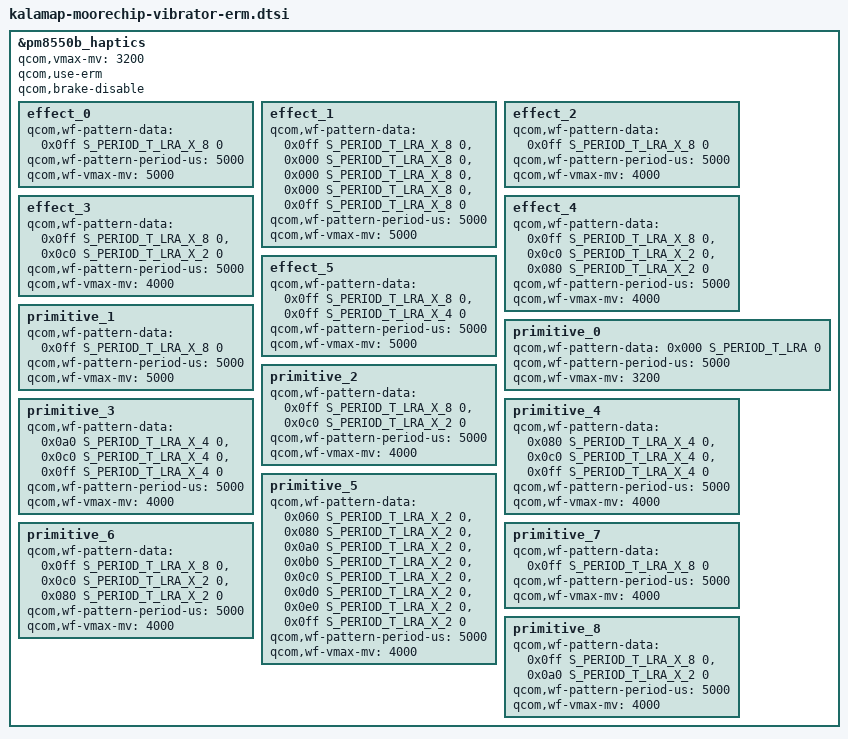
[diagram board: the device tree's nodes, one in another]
&pm8550b_haptics {
	status = "okay";
	qcom,vmax-mv = <3200>;
	qcom,use-erm;
	qcom,brake-disable;
	/delete-property/ qcom,lra-period-us;
	/delete-property/ qcom,brake-mode;
	/delete-property/ qcom,brake-pattern;
	/delete-property/ qcom,drv-sig-shape;
	/delete-property/ qcom,brake-sig-shape;

	effect_0 {
		/* CLICK */
		qcom,wf-pattern-data = <0x0ff S_PERIOD_T_LRA_X_8 0>;
		qcom,wf-pattern-period-us = <5000>;
		/delete-property/ qcom,wf-pattern-preload;
		qcom,wf-vmax-mv = <5000>;
	};

	effect_1 {
		/* DOUBLE_CLICK */
		qcom,wf-pattern-data =  <0x0ff S_PERIOD_T_LRA_X_8 0>,
					<0x000 S_PERIOD_T_LRA_X_8 0>,
					<0x000 S_PERIOD_T_LRA_X_8 0>,
					<0x000 S_PERIOD_T_LRA_X_8 0>,
					<0x0ff S_PERIOD_T_LRA_X_8 0>;
		qcom,wf-pattern-period-us = <5000>;
		qcom,wf-vmax-mv = <5000>;
	};

	effect_2 {
		/* TICK */
		qcom,wf-pattern-data = <0x0ff S_PERIOD_T_LRA_X_8 0>;
		qcom,wf-pattern-period-us = <5000>;
		qcom,wf-vmax-mv = <4000>;
	};

	effect_3 {
		/* THUD */
		qcom,wf-pattern-data =  <0x0ff S_PERIOD_T_LRA_X_8 0>,
					<0x0c0 S_PERIOD_T_LRA_X_2 0>;
		qcom,wf-pattern-period-us = <5000>;
		qcom,wf-vmax-mv = <4000>;
	};

	effect_4 {
		/* POP */
		qcom,wf-pattern-data =  <0x0ff S_PERIOD_T_LRA_X_8 0>,
					<0x0c0 S_PERIOD_T_LRA_X_2 0>,
					<0x080 S_PERIOD_T_LRA_X_2 0>;
		qcom,wf-pattern-period-us = <5000>;
		qcom,wf-vmax-mv = <4000>;
	};

	effect_5 {
		/* HEAVY CLICK */
		qcom,wf-pattern-data =  <0x0ff S_PERIOD_T_LRA_X_8 0>,
					<0x0ff S_PERIOD_T_LRA_X_4 0>;
		qcom,wf-pattern-period-us = <5000>;
		qcom,wf-vmax-mv = <5000>;
	};

	primitive_0 {
		/* NOOP */
		qcom,wf-pattern-data = <0x000 S_PERIOD_T_LRA 0>;
		qcom,wf-pattern-period-us = <5000>;
		qcom,wf-vmax-mv = <3200>;
	};

	primitive_1 {
		/* CLICK */
		qcom,wf-pattern-data = <0x0ff S_PERIOD_T_LRA_X_8 0>;
		qcom,wf-pattern-period-us = <5000>;
		qcom,wf-vmax-mv = <5000>;
	};

	primitive_2 {
		/* THUD */
		qcom,wf-pattern-data =  <0x0ff S_PERIOD_T_LRA_X_8 0>,
					<0x0c0 S_PERIOD_T_LRA_X_2 0>;
		qcom,wf-pattern-period-us = <5000>;
		qcom,wf-vmax-mv = <4000>;
	};

	primitive_3 {
		/* SPIN */
		qcom,wf-pattern-data =  <0x0a0 S_PERIOD_T_LRA_X_4 0>,
					<0x0c0 S_PERIOD_T_LRA_X_4 0>,
					<0x0ff S_PERIOD_T_LRA_X_4 0>;
		qcom,wf-pattern-period-us = <5000>;
		qcom,wf-vmax-mv = <4000>;
	};

	primitive_4 {
		/* QUICK_RISE */
		qcom,wf-pattern-data =  <0x080 S_PERIOD_T_LRA_X_4 0>,
					<0x0c0 S_PERIOD_T_LRA_X_4 0>,
					<0x0ff S_PERIOD_T_LRA_X_4 0>;
		qcom,wf-pattern-period-us = <5000>;
		qcom,wf-vmax-mv = <4000>;
	};

	primitive_5 {
		/* SLOW_RISE */
		qcom,wf-pattern-data =  <0x060 S_PERIOD_T_LRA_X_2 0>,
					<0x080 S_PERIOD_T_LRA_X_2 0>,
					<0x0a0 S_PERIOD_T_LRA_X_2 0>,
					<0x0b0 S_PERIOD_T_LRA_X_2 0>,
					<0x0c0 S_PERIOD_T_LRA_X_2 0>,
					<0x0d0 S_PERIOD_T_LRA_X_2 0>,
					<0x0e0 S_PERIOD_T_LRA_X_2 0>,
					<0x0ff S_PERIOD_T_LRA_X_2 0>;
		qcom,wf-pattern-period-us = <5000>;
		qcom,wf-vmax-mv = <4000>;
	};

	primitive_6 {
		/* QUICK_FALL */
		qcom,wf-pattern-data =  <0x0ff S_PERIOD_T_LRA_X_8 0>,
					<0x0c0 S_PERIOD_T_LRA_X_2 0>,
					<0x080 S_PERIOD_T_LRA_X_2 0>;
		qcom,wf-pattern-period-us = <5000>;
		qcom,wf-vmax-mv = <4000>;
	};

	primitive_7 {
		/* LIGHT_TICK */
		qcom,wf-pattern-data = <0x0ff S_PERIOD_T_LRA_X_8 0>;
		qcom,wf-pattern-period-us = <5000>;
		qcom,wf-vmax-mv = <4000>;
	};

	primitive_8 {
		/* LOW_TICK */
		qcom,wf-pattern-data =  <0x0ff S_PERIOD_T_LRA_X_8 0>,
					<0x0a0 S_PERIOD_T_LRA_X_2 0>;
		qcom,wf-pattern-period-us = <5000>;
		qcom,wf-vmax-mv = <4000>;
	};
};
